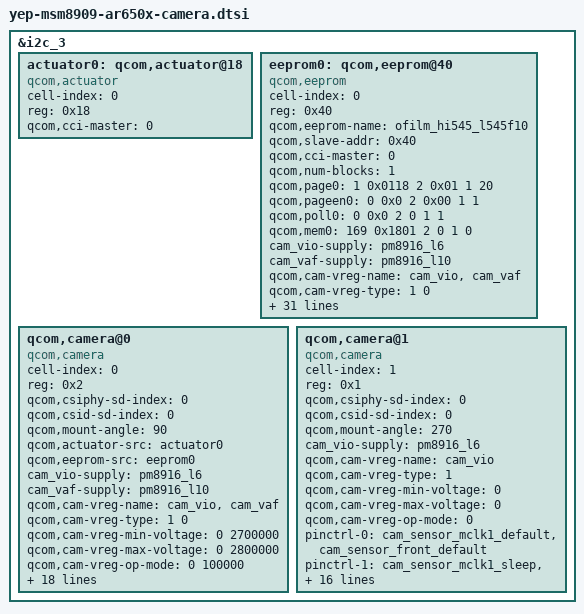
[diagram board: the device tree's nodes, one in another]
/*
 * Copyright (c) 2014, The Linux Foundation. All rights reserved.
 *
 * This program is free software; you can redistribute it and/or modify
 * it under the terms of the GNU General Public License version 2 and
 * only version 2 as published by the Free Software Foundation.
 *
 * This program is distributed in the hope that it will be useful,
 * but WITHOUT ANY WARRANTY; without even the implied warranty of
 * MERCHANTABILITY or FITNESS FOR A PARTICULAR PURPOSE.  See the
 * GNU General Public License for more details.
 */
 
/*  Date            Author          Why
    2015-05-18      yuquan          creat
*/ 
&i2c_3 {
	actuator0: qcom,actuator@18 {
		cell-index = <0>;
		reg = <0x18>;
		compatible = "qcom,actuator";
		qcom,cci-master = <0>;
	};
	eeprom0: qcom,eeprom@40 {
		cell-index = <0>;
		reg = <0x40>;
		qcom,eeprom-name = "ofilm_hi545_l545f10";
		compatible = "qcom,eeprom";
		qcom,slave-addr = <0x40>;
		qcom,cci-master = <0>;
		qcom,num-blocks = <1>;
		/*sensor_init*/	
		qcom,page0 = <1 0x0118 2 0x01 1 20>;
		qcom,pageen0 = <0 0x0 2 0x00 1 1>;
		qcom,poll0= <0 0x0 2 0 1 1>;
		qcom,mem0 = <169 0x1801 2 0 1 0>;	
		cam_vio-supply = <&pm8916_l6>;
		cam_vaf-supply = <&pm8916_l10>;
		qcom,cam-vreg-name = "cam_vio","cam_vaf";
		qcom,cam-vreg-type = <1 0>;
		qcom,cam-vreg-min-voltage = <0 2700000>;
		qcom,cam-vreg-max-voltage = <0 2800000>;
		qcom,cam-vreg-op-mode = <0 100000>;
		pinctrl-names = "cam_default", "cam_suspend";
		pinctrl-0 = <&cam_sensor_mclk0_default
		             &cam_sensor_rear_default>;
		pinctrl-1 = <&cam_sensor_mclk0_sleep &cam_sensor_rear_sleep>;		
		qcom,gpio-no-mux = <0>;	
		gpios = <&msm_gpio 26 0>,
		        <&msm_gpio 35 0>,
		        <&msm_gpio 34 0>,
		        <&msm_gpio 92 0>;
		qcom,gpio-reset = <1>;
		qcom,gpio-standby = <2>;
		qcom,gpio-vana = <3>;
		qcom,gpio-req-tbl-num = <0 1 2 3>;
		qcom,gpio-req-tbl-flags = <1 0 0 0>;
		qcom,gpio-req-tbl-label = "CAMIF_MCLK",
					  "CAM_RESET",
					  "CAM_STANDBY",
					  "CAM_VANA";
		qcom,cam-power-seq-type = "sensor_gpio",
		                          "sensor_gpio",
					  "sensor_vreg",
					  "sensor_gpio",
					  "sensor_vreg",
					  "sensor_gpio",
					  "sensor_clk",
					  "sensor_gpio",
					  "sensor_i2c_mux";
		qcom,cam-power-seq-val = "sensor_gpio_standby",
		                         "sensor_gpio_reset",
					 "cam_vio",
					 "sensor_gpio_vana",
					 "cam_vaf",
					 "sensor_gpio_standby",
					 "sensor_cam_mclk",
					 "sensor_gpio_reset",
					 "none";
		qcom,cam-power-seq-cfg-val = <0 0 0 1 0 1 24000000 1 0>;
		qcom,cam-power-seq-delay = <0 0 0 0 0 5 10 10 0>;
		clocks = <&clock_gcc clk_mclk0_clk_src>,
		         <&clock_gcc clk_gcc_camss_mclk0_clk>;
		clock-names = "cam_src_clk", "cam_clk";
	};
	
	qcom,camera@0 {
		cell-index = <0>;
		compatible = "qcom,camera";
		reg = <0x2>;
		qcom,csiphy-sd-index = <0>;
		qcom,csid-sd-index = <0>;
		qcom,mount-angle = <90>;
		qcom,actuator-src = <&actuator0>;
		qcom,eeprom-src = <&eeprom0>;
		cam_vio-supply = <&pm8916_l6>;
		cam_vaf-supply = <&pm8916_l10>;
		qcom,cam-vreg-name = "cam_vio","cam_vaf";
		qcom,cam-vreg-type = <1 0>;
		qcom,cam-vreg-min-voltage = <0 2700000>;
		qcom,cam-vreg-max-voltage = <0 2800000>;
		qcom,cam-vreg-op-mode = <0 100000>;
		pinctrl-names = "cam_default", "cam_suspend";
		pinctrl-0 = <&cam_sensor_mclk0_default
				&cam_sensor_rear_default>;
		pinctrl-1 = <&cam_sensor_mclk0_sleep &cam_sensor_rear_sleep>;
		gpios = <&msm_gpio 26 0>,
			<&msm_gpio 35 0>,
			<&msm_gpio 34 0>,
			<&msm_gpio 92 0>;
		qcom,gpio-reset = <1>;
		qcom,gpio-standby = <2>;
		qcom,gpio-vana = <3>;
		qcom,gpio-req-tbl-num = <0 1 2 3>;
		qcom,gpio-req-tbl-flags = <1 0 0 0>;
		qcom,gpio-req-tbl-label = "CAMIF_MCLK",
			"CAM_RESET",
			"CAM_STANDBY",
			"CAM_VANA";
		qcom,sensor-position = <0>;
		qcom,sensor-mode = <0>;
		qcom,cci-master = <0>;
		status = "ok";
		clocks = <&clock_gcc clk_mclk0_clk_src>,
				<&clock_gcc clk_gcc_camss_mclk0_clk>;
		clock-names = "cam_src_clk", "cam_clk";
	};

	qcom,camera@1 {
		cell-index = <1>;
		compatible = "qcom,camera";
		reg = <0x1>;
		qcom,csiphy-sd-index = <0>;
		qcom,csid-sd-index = <0>;
		qcom,mount-angle = <270>;
		cam_vio-supply = <&pm8916_l6>;
		qcom,cam-vreg-name = "cam_vio";
		qcom,cam-vreg-type = <1>;
		qcom,cam-vreg-min-voltage = <0>;
		qcom,cam-vreg-max-voltage = <0>;
		qcom,cam-vreg-op-mode = <0>;
		pinctrl-names = "cam_default", "cam_suspend";
		pinctrl-0 = <&cam_sensor_mclk1_default &cam_sensor_front_default>;
		pinctrl-1 = <&cam_sensor_mclk1_sleep &cam_sensor_front_sleep>;
		gpios = <&msm_gpio 27 0>,
			<&msm_gpio 28 0>,
			<&msm_gpio 33 0>,
			<&msm_gpio 23 0>,
			<&msm_gpio 92 0>;
		qcom,gpio-reset = <1>;
		qcom,gpio-standby = <2>;
		qcom,gpio-cameraid = <3>;
		qcom,gpio-vana = <4>;
		qcom,gpio-req-tbl-num = <0 1 2 3 4>;
		qcom,gpio-req-tbl-flags = <1 0 0 1 0>;
		qcom,gpio-req-tbl-label = "CAMIF_MCLK",
			"CAM_RESET",
			"CAM_STANDBY",
			"CAM_ID",
			"CAM_VANA";
		qcom,sensor-position = <1>;
		qcom,sensor-mode = <0>;
		qcom,cci-master = <0>;
		status = "ok";
		clocks = <&clock_gcc clk_mclk1_clk_src>,
				<&clock_gcc clk_gcc_camss_mclk1_clk>;
		clock-names = "cam_src_clk", "cam_clk";
	};
	
};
